# GD32H71x_72x register map
File version: 1.0
CPU: CM7 r1p2, little endian, MPU, FPU, 4 interrupt priority bits
Registers are 32-bit, read-write, reset 0x0 unless marked. A register's access mark holds for its fields unless they carry their own. Offsets are from the block's base; [hi:lo] are bit positions; lines under a group give offsets from that group; 'fields as' and 'values as' point back to an identical list.

## SAI0 — Serial Audio Interface
Base 0x40015800
Same registers: SAI1 0x40015C00, SAI2 0x40016000, SAI3 0x40016800
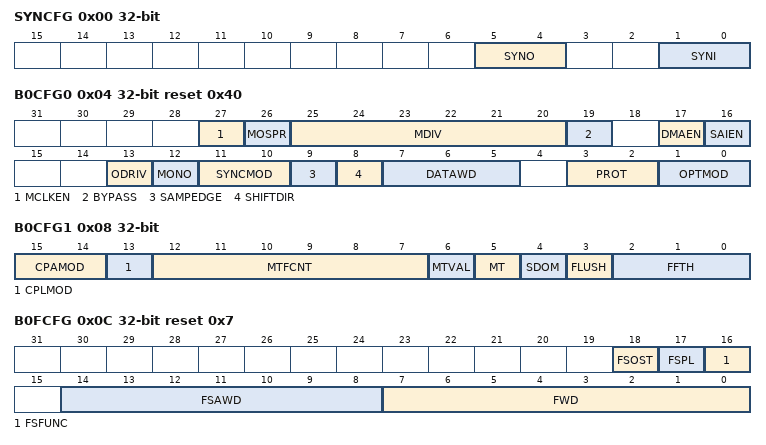
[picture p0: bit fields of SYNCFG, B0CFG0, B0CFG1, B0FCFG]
0x00 SYNCFG — Synchronize configuration register
  [5:4] SYNO — Synchronization outputs
  [1:0] SYNI — Synchronization inputs
0x04 B0CFG0 reset 0x40 — Block 0 configuration registe
  [27] MCLKEN — The master clock enable
  [26] MOSPR — The master clock oversampling rate
  [25:20] MDIV — Master clock divider ratio
  [19] BYPASS — Clock divider logic bypass
  [17] DMAEN — DMA enable
  [16] SAIEN — SAI sub-block enable
  [13] ODRIV — Output Drive
  [12] MONO — Stereo and Mono mode selection
  [11:10] SYNCMOD — Synchronization mode
  [9] SAMPEDGE — Sampling clock edge
  [8] SHIFTDIR — Shift direction
  [7:5] DATAWD — Data width
  [3:2] PROT — Protocol selection
  [1:0] OPTMOD — Operating mode
0x08 B0CFG1 — Block 0 configuration registe
  [15:14] CPAMOD — Compander mode
  [13] CPLMOD — Complement mode
  [12:7] MTFCNT — Mute frame count
  [6] MTVAL — Mute value
  [5] MT — Mute
  [4] SDOM — Serial data output management
  [3] FLUSH — FIFO flush
  [2:0] FFTH — FIFO threshold
0x0C B0FCFG reset 0x7 — Block 0 frame configuration regist
  [18] FSOST — Frame synchronization offset
  [17] FSPL — Frame synchronization active polarity
  [16] FSFUNC — Frame synchronization function
  [14:8] FSAWD — Frame synchronization active width
  [7:0] FWD — Frame width
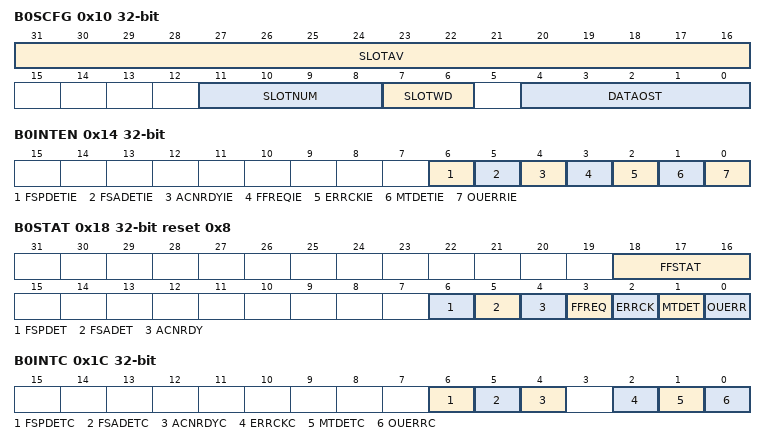
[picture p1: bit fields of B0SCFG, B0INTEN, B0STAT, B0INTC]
0x10 B0SCFG — Block 0 slot configuration regist
  [31:16] SLOTAV — Slot activation vector
  [11:8] SLOTNUM — Slot number within frame
  [7:6] SLOTWD — Slot width
  [4:0] DATAOST — Data offset
0x14 B0INTEN — Block 0 interrupt enable regist
  [6] FSPDETIE — Frame synchronization postpone detection interrupt enable
  [5] FSADETIE — Frame synchronization advanced detection interrupt enable
  [4] ACNRDYIE — Audio codec not ready interrupt enable
  [3] FFREQIE — FIFO request interrupt enable
  [2] ERRCKIE — Error clock interrupt enable
  [1] MTDETIE — Mute detection interrupt enable
  [0] OUERRIE — FIFO overrun or underrun interrupt enable
0x18 B0STAT ro reset 0x8 — Block 0 status regist
  [18:16] FFSTAT — FIFO status
  [6] FSPDET — Frame synchronization postponed detection
  [5] FSADET — Frame synchronization advanced detection
  [4] ACNRDY — Audio codec not ready
  [3] FFREQ — FIFO request
  [2] ERRCK — Error clock
  [1] MTDET — Mute detection
  [0] OUERR — Overrun or underrun
0x1C B0INTC — Block 0 interrupt flag clear regist
  [6] FSPDETC — Frame synchronization postponed detection interrupt clear
  [5] FSADETC — Frame synchronization advanced detection interrupt clear
  [4] ACNRDYC — Audio codec not ready interrupt clear
  [2] ERRCKC — Clock error interrupt clear
  [1] MTDETC — Mute detection interrupt clear
  [0] OUERRC — Overrun or underrun interrupt clear
0x20 B0DATA — Block 0 data regist
  [31:0] DATA
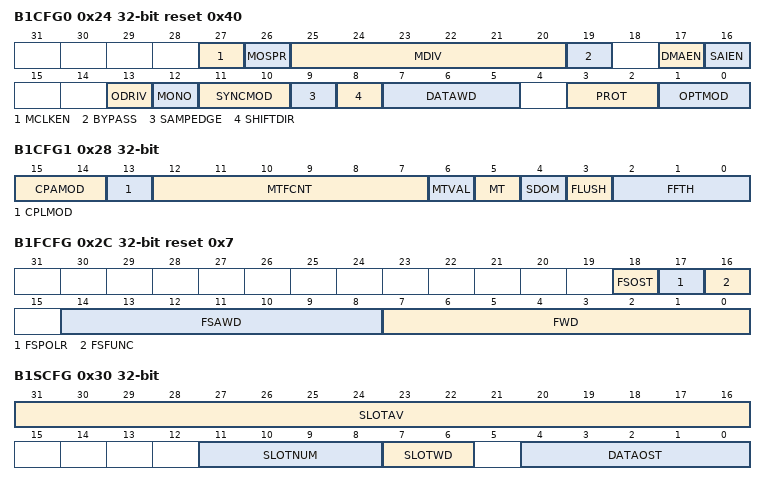
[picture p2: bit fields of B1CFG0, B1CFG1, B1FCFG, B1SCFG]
0x24 B1CFG0 reset 0x40 — Block 1 configuration registe
  fields as B0CFG0
0x28 B1CFG1 — Block 1 configuration registe
  fields as B0CFG1
0x2C B1FCFG reset 0x7 — Block 1 frame configuration regist
  [18] FSOST — Frame synchronization offset
  [17] FSPOLR — Frame synchronization active polarity
  [16] FSFUNC — Frame synchronization function
  [14:8] FSAWD — Frame synchronization active width
  [7:0] FWD — Frame width
0x30 B1SCFG — Block 1 slot configuration regist
  fields as B0SCFG
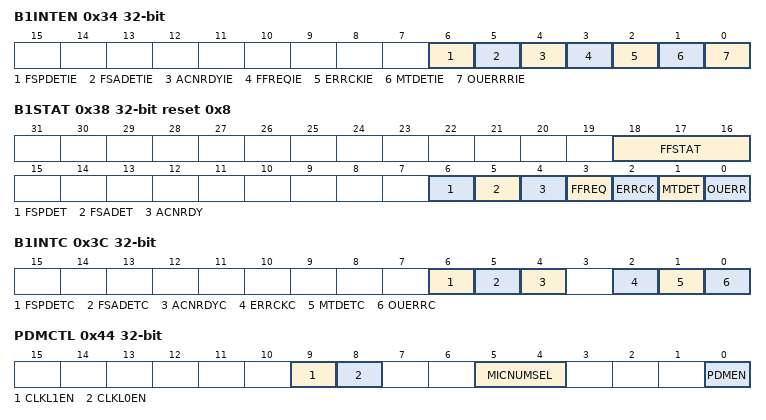
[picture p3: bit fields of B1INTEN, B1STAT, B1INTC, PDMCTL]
0x34 B1INTEN — Block 1 interrupt enable regist
  [6] FSPDETIE — Frame synchronization postpone detection interrupt enable
  [5] FSADETIE — Frame synchronization advanced detection interrupt enable
  [4] ACNRDYIE — Audio codec not ready interrupt enable
  [3] FFREQIE — FIFO request interrupt enable
  [2] ERRCKIE — Error clock interrupt enable
  [1] MTDETIE — Mute detection interrupt enable
  [0] OUERRRIE — FIFO overrun or underrun interrupt enable
0x38 B1STAT ro reset 0x8 — Block 1 status regist
  fields as B0STAT
0x3C B1INTC — Block 1 interrupt flag clear regist
  fields as B0INTC
0x40 B1DATA — Block 1 data regist
  [31:0] DATA
0x44 PDMCTL — PDM control register
  [9] CLKL1EN — PDM clock line 1 enable
  [8] CLKL0EN — PDM clock line 0 enable
  [5:4] MICNUMSEL — Select microphones number
  [0] PDMEN — PDM enable
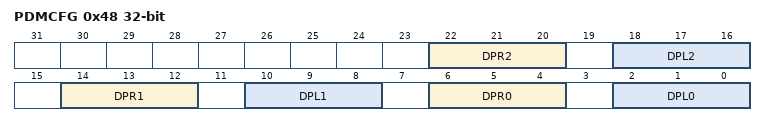
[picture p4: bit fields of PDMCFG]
0x48 PDMCFG — PDM configuration register
  [22:20] DPR2 — The 2nd group of right channel microphone data flow delay period
  [18:16] DPL2 — The 2nd group of left channel microphone data flow delay period
  [14:12] DPR1 — The 1st group of right channel microphone data flow delay period
  [10:8] DPL1 — The 1st group of left channel microphone data flow delay period
  [6:4] DPR0 — The 0 group of right channel microphone data flow delay period
  [2:0] DPL0 — The 0 group of left channel microphone data flow delay period
